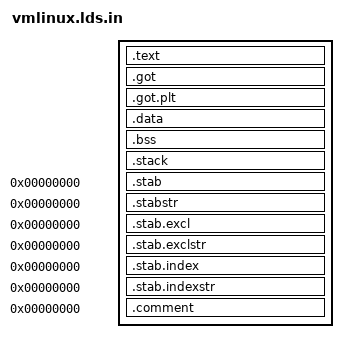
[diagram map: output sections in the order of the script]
/* ld script to make csky Linux kernel */

OUTPUT_ARCH(csky) 

ENTRY(_start)
SECTIONS
{
  _text = .;

  .text : {
    _start = .;
    *(.start)
    *(.text)
    *(.text.*)
    *(.fixup)
    *(.gnu.warning)
    *(.rodata)
    *(.rodata.*)
    *(.glue_7)
    *(.glue_7t)
    *(.piggydata)
    _image_length_addr = .;
    . = ALIGN(4);
  }

  _etext = .;

  _got_start = .;
  .got			: { *(.got) }
  _got_end = .;
  .got.plt		: { *(.got.plt) }
  .data			: { *(.data) }
  _edata = .;

  _sbss = .;
  .bss			: { *(.bss) }
  _ebss = .;


  .stack (NOLOAD)	: { *(.stack) }

  .stab 0		: { *(.stab) }
  .stabstr 0		: { *(.stabstr) }
  .stab.excl 0		: { *(.stab.excl) }
  .stab.exclstr 0	: { *(.stab.exclstr) }
  .stab.index 0		: { *(.stab.index) }
  .stab.indexstr 0	: { *(.stab.indexstr) }
  .comment 0		: { *(.comment) }
}
